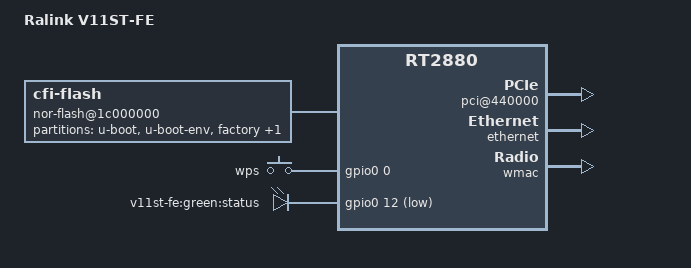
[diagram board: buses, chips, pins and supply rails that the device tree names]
/dts-v1/;

#include "rt2880.dtsi"

/ {
	compatible = "V11ST-FE", "ralink,rt2880-soc";
	model = "Ralink V11ST-FE";

	pci@440000 {
		status = "okay";

		host-bridge {
			pci-bridge@1 {
				status = "okay";
			};
		};
	};

	nor-flash@1c000000 {
		compatible = "cfi-flash";
		reg = <0x1c000000 0x800000>;
		bank-width = <2>;
		#address-cells = <1>;
		#size-cells = <1>;

		partition@0 {
			reg = <0x0 0x0030000>;
			label = "u-boot";
			read-only;
		};

		partition@30000 {
			reg = <0x00030000 0x00010000>;
			label = "u-boot-env";
			read-only;
		};

		factory: partition@40000 {
			reg = <0x00040000 0x00010000>;
			label = "factory";
			read-only;
		};

		partition@50000 {
			reg = <0x00050000 0x003b0000>;
			label = "firmware";
		};
	};

	gpio-keys-polled {
		compatible = "gpio-keys-polled";
		#address-cells = <1>;
		#size-cells = <0>;
		poll-interval = <100>;

		wps {
			label = "wps";
			gpios = <&gpio0 0 0>;
			linux,code = <0x211>;
		};
	};

	gpio-leds {
		compatible = "gpio-leds";

		status {
			label = "v11st-fe:green:status";
			gpios = <&gpio0 12 1>;
		};
	};
};

&gpio0 {
	status = "okay";
};

&ethernet {
	status = "okay";
};

&wmac {
	ralink,mtd-eeprom = <&factory 0>;
};
